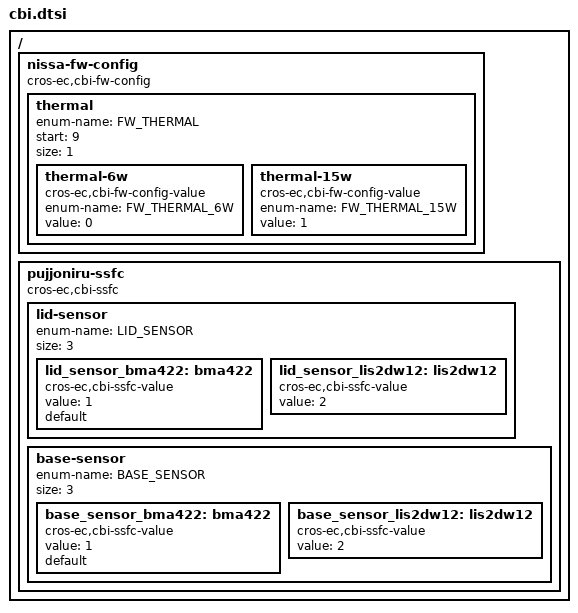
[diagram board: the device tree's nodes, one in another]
/* Copyright 2025 The ChromiumOS Authors
 * Use of this source code is governed by a BSD-style license that can be
 * found in the LICENSE file.
 */

/ {
	nissa-fw-config {
		compatible = "cros-ec,cbi-fw-config";

		thermal {
			enum-name = "FW_THERMAL";
			start = <9>;
			size = <1>;

			thermal-6w {
				compatible = "cros-ec,cbi-fw-config-value";
				enum-name = "FW_THERMAL_6W";
				value = <0>;
			};
			thermal-15w {
				compatible = "cros-ec,cbi-fw-config-value";
				enum-name = "FW_THERMAL_15W";
				value = <1>;
			};
		};
	};

	pujjoniru-ssfc {
		compatible = "cros-ec,cbi-ssfc";

		/* SSFC field to identify lid motion sensor. */
		lid-sensor {
			enum-name = "LID_SENSOR";
			size = <3>;

			lid_sensor_bma422: bma422 {
				compatible = "cros-ec,cbi-ssfc-value";
				status = "okay";
				value = <1>;
				default;
			};
			lid_sensor_lis2dw12: lis2dw12 {
				compatible = "cros-ec,cbi-ssfc-value";
				status = "okay";
				value = <2>;
			};
		};

		/* SSFC field to identify base motion sensor. */
		base-sensor {
			enum-name = "BASE_SENSOR";
			size = <3>;

			base_sensor_bma422: bma422 {
				compatible = "cros-ec,cbi-ssfc-value";
				status = "okay";
				value = <1>;
				default;
			};
			base_sensor_lis2dw12: lis2dw12 {
				compatible = "cros-ec,cbi-ssfc-value";
				status = "okay";
				value = <2>;
			};
		};
	};
};
